# CY8C5868AXI_LP035 register map
File version: 0.1
Registers are 8-bit, read-write, no defined reset value unless marked. A register's access mark holds for its fields unless they carry their own. Offsets are from the block's base; [hi:lo] are bit positions; 'fields as' and 'values as' point back to an identical list.

## Control_Reg_2
Base 0x40006579
0x00 Control_Reg_2_CONTROL_REG

## Control_Reg_3
Base 0x4000647D
Registers as Control_Reg_2 (with Control_Reg_2 read as Control_Reg_3).

## Control_Reg_1
Base 0x40006577
Registers as Control_Reg_2 (with Control_Reg_2 read as Control_Reg_1).

## I2C_1
Base 0x400049C8
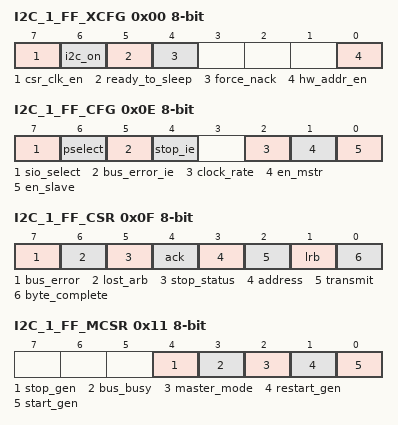
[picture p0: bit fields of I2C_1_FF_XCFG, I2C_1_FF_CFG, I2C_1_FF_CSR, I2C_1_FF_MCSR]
0x00 I2C_1_FF_XCFG — Extended Configuration Register: I2C_XCFG
  [7] csr_clk_en, [6] i2c_on, [5] ready_to_sleep ro, [4] force_nack, [0] hw_addr_en
0x02 I2C_1_FF_ADDR — Slave Adddress Register: I2C_ADR
  [6:0] slave_address — This register holds the slave's 7-bit address.
0x0E I2C_1_FF_CFG — Configuration Register: I2C_CFG
  [7] sio_select, [6] pselect, [5] bus_error_ie, [4] stop_ie, [2] clock_rate, [1] en_mstr, [0] en_slave
0x0F I2C_1_FF_CSR — Control and Status Register: I2C_CSR
  [7] bus_error, [6] lost_arb, [5] stop_status, [4] ack, [3] address, [2] transmit, [1] lrb, [0] byte_complete
0x10 I2C_1_FF_DATA — Data Register: I2C_D
  [7:0] data — This register provides read/write access to the Shift register.
0x11 I2C_1_FF_MCSR — Master Control and Status Register: I2C_MCSR
  [4] stop_gen, [3] bus_busy ro, [2] master_mode ro, [1] restart_gen, [0] start_gen
0x13 I2C_1_FF__CLK_DIV1 — Divider of BUS_CLK low part: I2C_CLK_DIV1
  [7:0] Div
0x14 I2C_1_FF__CLK_DIV2 — Divider high part: I2C_CLK_DIV1
  [1:0] Div
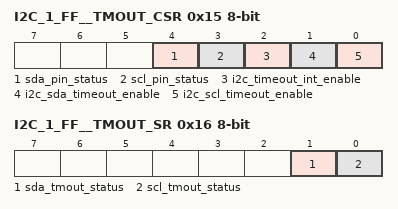
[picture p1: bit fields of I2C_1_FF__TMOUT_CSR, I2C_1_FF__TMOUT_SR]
0x15 I2C_1_FF__TMOUT_CSR — Extended Configuration Register: I2C_TMOUT_CSR
  [4] sda_pin_status, [3] scl_pin_status, [2] i2c_timeout_int_enable ro, [1] i2c_sda_timeout_enable, [0] i2c_scl_timeout_enable
0x16 I2C_1_FF__TMOUT_SR — Extended Configuration Register: I2C_TMOUT_SR
  [1] sda_tmout_status, [0] scl_tmout_status
0x17 I2C_1_FF__TMOUT_CFG0 — Extended Configuration Register: TMOUT_CFG0
  [7:0] timeout_period_lowbyte
0x18 I2C_1_FF__TMOUT_CFG1 — Extended Configuration Register: TMOUT_CFG1
  [3:0] timeout_period_highnibble

## Status_Reg_2
Base 0x4000656A
0x00 Status_Reg_2_STATUS_REG
0x20 Status_Reg_2_MASK_REG
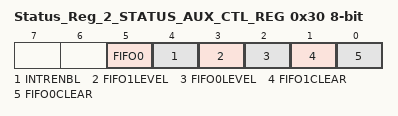
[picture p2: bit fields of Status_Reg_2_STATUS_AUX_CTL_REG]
0x30 Status_Reg_2_STATUS_AUX_CTL_REG
  [5] FIFO0 — FIFO0 clear
    1=ENABLED (Enable counter); 0=DISABLED (Disable counter)
  [4] INTRENBL — Enables or disables the Interrupt
    1=ENABLED (Interrupt enabled); 0=DISABLED (Interrupt disabled)
  [3] FIFO1LEVEL — FIFO level
    1=ENABLED (FIFO LVL: input mode: FIFO at least 1/2 empty; output mode: FIFO at least 1/2 full); 0=DISABLED (FIFO LVL: input mode: FIFO not full; output mode: FIFO not empty)
  [2] FIFO0LEVEL — FIFO level
    values as FIFO1LEVEL
  [1] FIFO1CLEAR — FIFO clear
    1=ENABLED (Clear FIFO state); 0=DISABLED (Normal FIFO operation)
  [0] FIFO0CLEAR — FIFO clear
    values as FIFO1CLEAR

## Status_Reg_3
Base 0x4000646D
Registers as Status_Reg_2 (with Status_Reg_2 read as Status_Reg_3).

## Status_Reg_1
Base 0x40006462
Registers as Status_Reg_2 (with Status_Reg_2 read as Status_Reg_1).

## SPIS_1
Base 0x40006409
0x00 SPIS_1_RX_DATA — SPIS RX Data
0x00 SPIS_1_TX_DATA — SPIS TX Data
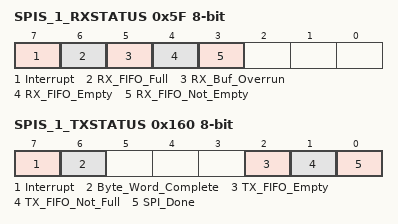
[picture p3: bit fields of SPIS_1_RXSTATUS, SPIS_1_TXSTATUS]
0x5F SPIS_1_RXSTATUS — SPIS RX Status Register
  [7] Interrupt ro — Set when interrupt occurs
  [6] RX_FIFO_Full ro — Set when the RX Data FIFO is full
  [5] RX_Buf_Overrun ro — Set when RX Data has overrun the 4 byte/word FIFO without being moved to the RX buffer cmemory array (if one exists)
  [4] RX_FIFO_Empty ro — Set when the RX Data FIFO is empty
  [3] RX_FIFO_Not_Empty ro — Set when the RX Data FIFO is not empty. That is, at least one byte/word is in the RX FIFO
0x160 SPIS_1_TXSTATUS — SPIS TX Status Register
  [7] Interrupt ro — Set when interrupt occurs
  [6] Byte_Word_Complete ro — Set when a byte/word transmit has completed
  [2] TX_FIFO_Empty ro — Set when the TX Data FIFO is empty
  [1] TX_FIFO_Not_Full ro — Set when the TX Data FIFO is not full
  [0] SPI_Done ro — Set when all of the data in the transmit FIFO has been sent. Set when Byte/Word Complete has been set and TX Data FIFO is empty
